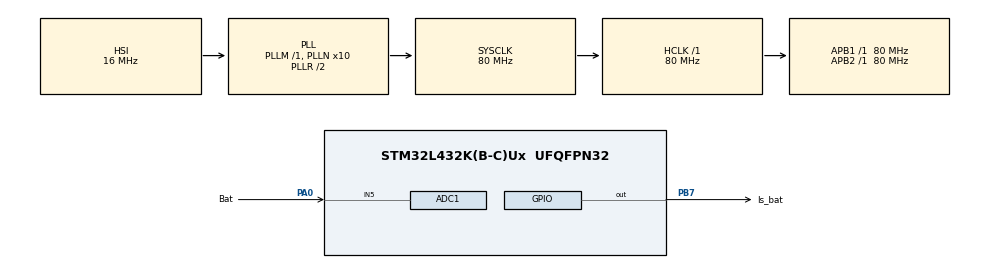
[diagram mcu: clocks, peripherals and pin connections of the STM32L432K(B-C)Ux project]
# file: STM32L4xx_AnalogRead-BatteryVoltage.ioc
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ADC1.Channel-0\#ChannelRegularConversion=ADC_CHANNEL_5
ADC1.ContinuousConvMode=ENABLE
ADC1.NbrOfConversionFlag=1
ADC1.OffsetNumber-0\#ChannelRegularConversion=ADC_OFFSET_NONE
ADC1.Rank-0\#ChannelRegularConversion=1
ADC1.SamplingTime-0\#ChannelRegularConversion=ADC_SAMPLETIME_2CYCLES_5
ADC1.master=1
Mcu.Family=STM32L4
Mcu.Name=STM32L432K(B-C)Ux
Mcu.Package=UFQFPN32
NVIC.ADC1_IRQn=true\:0\:0\:false\:false\:true\:true\:true\:true
NVIC.PriorityGroup=NVIC_PRIORITYGROUP_4
NVIC.RTC_WKUP_IRQn=true\:0\:0\:false\:false\:true\:true\:true\:true
PA0.GPIO_Label=Bat
PA0.Signal=ADCx_IN5
PA13\ (JTMS-SWDIO).Mode=Trace_Asynchronous_SW
PA13\ (JTMS-SWDIO).Signal=SYS_JTMS-SWDIO
PA14\ (JTCK-SWCLK).Mode=Trace_Asynchronous_SW
PA14\ (JTCK-SWCLK).Signal=SYS_JTCK-SWCLK
PB3\ (JTDO-TRACESWO).Mode=Trace_Asynchronous_SW
PB3\ (JTDO-TRACESWO).Signal=SYS_JTDO-SWO
PB7.GPIO_Label=ls_bat
PB7.Signal=GPIO_Output
PC14-OSC32_IN\ (PC14).Mode=LSE-External-Oscillator
PC14-OSC32_IN\ (PC14).Signal=RCC_OSC32_IN
PC15-OSC32_OUT\ (PC15).Mode=LSE-External-Oscillator
PC15-OSC32_OUT\ (PC15).Signal=RCC_OSC32_OUT
ProjectManager.HeapSize=0x200
ProjectManager.StackSize=0x400
ProjectManager.TargetToolchain=STM32CubeIDE
RCC.ADCFreq_Value=64000000
RCC.AHBFreq_Value=80000000
RCC.APB1Freq_Value=80000000
RCC.APB1TimFreq_Value=80000000
RCC.APB2Freq_Value=80000000
RCC.APB2TimFreq_Value=80000000
RCC.CortexFreq_Value=80000000
RCC.HCLKFreq_Value=80000000
RCC.HSE_VALUE=8000000
RCC.HSI48_VALUE=48000000
RCC.HSI_VALUE=16000000
RCC.MSI_VALUE=4000000
RCC.PLLN=10
RCC.PLLSAI1Q=RCC_PLLQ_DIV4
RCC.PLLSourceVirtual=RCC_PLLSOURCE_HSI
RCC.RTCClockSelection=RCC_RTCCLKSOURCE_LSE
RCC.SYSCLKFreq_VALUE=80000000
RCC.SYSCLKSource=RCC_SYSCLKSOURCE_PLLCLK
RCC.USBFreq_Value=32000000
RCC.VCOOutputFreq_Value=160000000
RTC.WakeUpClock=RTC_WAKEUPCLOCK_CK_SPRE_16BITS
SH.ADCx_IN5.0=ADC1_IN5,IN5-Single-Ended
VP_RNG_VS_RNG.Mode=RNG_Activate
VP_RTC_VS_RTC_Activate.Mode=RTC_Enabled
VP_RTC_VS_RTC_Calendar.Mode=RTC_Calendar
VP_RTC_VS_RTC_WakeUp_intern.Mode=WakeUp
board=custom

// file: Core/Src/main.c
/* USER CODE BEGIN Header */
/**
  ******************************************************************************
  * @file           : main.c
  * @brief          : Main program body
  ******************************************************************************
  * @attention
  *
  * Copyright (c) 2023 STMicroelectronics.
  * All rights reserved.
  *
  * This software is licensed under terms that can be found in the LICENSE file
  * in the root directory of this software component.
  * If no LICENSE file comes with this software, it is provided AS-IS.
  *
  ******************************************************************************
  */
/* USER CODE END Header */
#include "main.h"
#include <stdio.h>

ADC_HandleTypeDef hadc1;

RNG_HandleTypeDef hrng;

RTC_HandleTypeDef hrtc;

void SystemClock_Config(void);
void PeriphCommonClock_Config(void);
static void MX_GPIO_Init(void);
static void MX_ADC1_Init(void);
static void MX_RNG_Init(void);
static void MX_RTC_Init(void);

/* USER CODE BEGIN 0 */
int _write(int file, char *ptr, int len){
     int DataIdx;
     for (DataIdx = 0; DataIdx < len; DataIdx++){
         ITM_SendChar((*ptr++));
     }
     return len;
}

void readBat(){
	uint8_t bat = 0;
	HAL_GPIO_WritePin(ls_bat_GPIO_Port, ls_bat_Pin, SET);
	HAL_Delay(100);
	HAL_ADCEx_Calibration_Start(&hadc1, ADC_SINGLE_ENDED);
	HAL_ADC_Start(&hadc1);
	HAL_ADC_PollForConversion(&hadc1, 20);
	float adc_val = 0;
	for (int i = 0; i < 100; i++) {
		adc_val += HAL_ADC_GetValue(&hadc1);
		HAL_Delay(5);
	}
	HAL_GPIO_WritePin(ls_bat_GPIO_Port, ls_bat_Pin, RESET);
	adc_val = adc_val / 100;
	float vadc = (adc_val / 4096) * 3.3;
	bat = ((vadc * (5.23 + 10) / 10) * 100) - 200;
	printf("battery voltage : %.2fV\n", (bat + 200)/100.0);
}
/* USER CODE END 0 */

int main(void)
{

  /* MCU Configuration--------------------------------------------------------*/

  /* Reset of all peripherals, Initializes the Flash interface and the Systick. */
  HAL_Init();

  /* Configure the system clock */
  SystemClock_Config();

/* Configure the peripherals common clocks */
  PeriphCommonClock_Config();

  /* Initialize all configured peripherals */
  MX_GPIO_Init();
  MX_ADC1_Init();
  MX_RNG_Init();
  MX_RTC_Init();

  /* Infinite loop */
  while (1)
  {

    /* USER CODE BEGIN 3 */
	  readBat();
	  HAL_Delay(500);
  }
  /* USER CODE END 3 */
}

void SystemClock_Config(void)
{
  RCC_OscInitTypeDef RCC_OscInitStruct = {0};
  RCC_ClkInitTypeDef RCC_ClkInitStruct = {0};

  /** Configure the main internal regulator output voltage
  */
  if (HAL_PWREx_ControlVoltageScaling(PWR_REGULATOR_VOLTAGE_SCALE1) != HAL_OK)
  {
    Error_Handler();
  }

  /** Configure LSE Drive Capability
  */
  HAL_PWR_EnableBkUpAccess();
  __HAL_RCC_LSEDRIVE_CONFIG(RCC_LSEDRIVE_LOW);

  /** Initializes the RCC Oscillators according to the specified parameters
  * in the RCC_OscInitTypeDef structure.
  */
  RCC_OscInitStruct.OscillatorType = RCC_OSCILLATORTYPE_HSI|RCC_OSCILLATORTYPE_LSE;
  RCC_OscInitStruct.LSEState = RCC_LSE_ON;
  RCC_OscInitStruct.HSIState = RCC_HSI_ON;
  RCC_OscInitStruct.HSICalibrationValue = RCC_HSICALIBRATION_DEFAULT;
  RCC_OscInitStruct.PLL.PLLState = RCC_PLL_ON;
  RCC_OscInitStruct.PLL.PLLSource = RCC_PLLSOURCE_HSI;
  RCC_OscInitStruct.PLL.PLLM = 1;
  RCC_OscInitStruct.PLL.PLLN = 10;
  RCC_OscInitStruct.PLL.PLLP = RCC_PLLP_DIV7;
  RCC_OscInitStruct.PLL.PLLQ = RCC_PLLQ_DIV2;
  RCC_OscInitStruct.PLL.PLLR = RCC_PLLR_DIV2;
  if (HAL_RCC_OscConfig(&RCC_OscInitStruct) != HAL_OK)
  {
    Error_Handler();
  }

  /** Initializes the CPU, AHB and APB buses clocks
  */
  RCC_ClkInitStruct.ClockType = RCC_CLOCKTYPE_HCLK|RCC_CLOCKTYPE_SYSCLK
                              |RCC_CLOCKTYPE_PCLK1|RCC_CLOCKTYPE_PCLK2;
  RCC_ClkInitStruct.SYSCLKSource = RCC_SYSCLKSOURCE_PLLCLK;
  RCC_ClkInitStruct.AHBCLKDivider = RCC_SYSCLK_DIV1;
  RCC_ClkInitStruct.APB1CLKDivider = RCC_HCLK_DIV1;
  RCC_ClkInitStruct.APB2CLKDivider = RCC_HCLK_DIV1;

  if (HAL_RCC_ClockConfig(&RCC_ClkInitStruct, FLASH_LATENCY_4) != HAL_OK)
  {
    Error_Handler();
  }
}

void PeriphCommonClock_Config(void)
{
  RCC_PeriphCLKInitTypeDef PeriphClkInit = {0};

  /** Initializes the peripherals clock
  */
  PeriphClkInit.PeriphClockSelection = RCC_PERIPHCLK_RNG|RCC_PERIPHCLK_ADC;
  PeriphClkInit.AdcClockSelection = RCC_ADCCLKSOURCE_PLLSAI1;
  PeriphClkInit.RngClockSelection = RCC_RNGCLKSOURCE_PLLSAI1;
  PeriphClkInit.PLLSAI1.PLLSAI1Source = RCC_PLLSOURCE_HSI;
  PeriphClkInit.PLLSAI1.PLLSAI1M = 1;
  PeriphClkInit.PLLSAI1.PLLSAI1N = 8;
  PeriphClkInit.PLLSAI1.PLLSAI1P = RCC_PLLP_DIV7;
  PeriphClkInit.PLLSAI1.PLLSAI1Q = RCC_PLLQ_DIV4;
  PeriphClkInit.PLLSAI1.PLLSAI1R = RCC_PLLR_DIV2;
  PeriphClkInit.PLLSAI1.PLLSAI1ClockOut = RCC_PLLSAI1_48M2CLK|RCC_PLLSAI1_ADC1CLK;
  if (HAL_RCCEx_PeriphCLKConfig(&PeriphClkInit) != HAL_OK)
  {
    Error_Handler();
  }
}

static void MX_ADC1_Init(void)
{

  ADC_ChannelConfTypeDef sConfig = {0};

  /** Common config
  */
  hadc1.Instance = ADC1;
  hadc1.Init.ClockPrescaler = ADC_CLOCK_ASYNC_DIV1;
  hadc1.Init.Resolution = ADC_RESOLUTION_12B;
  hadc1.Init.DataAlign = ADC_DATAALIGN_RIGHT;
  hadc1.Init.ScanConvMode = ADC_SCAN_DISABLE;
  hadc1.Init.EOCSelection = ADC_EOC_SINGLE_CONV;
  hadc1.Init.LowPowerAutoWait = DISABLE;
  hadc1.Init.ContinuousConvMode = ENABLE;
  hadc1.Init.NbrOfConversion = 1;
  hadc1.Init.DiscontinuousConvMode = DISABLE;
  hadc1.Init.ExternalTrigConv = ADC_SOFTWARE_START;
  hadc1.Init.ExternalTrigConvEdge = ADC_EXTERNALTRIGCONVEDGE_NONE;
  hadc1.Init.DMAContinuousRequests = DISABLE;
  hadc1.Init.Overrun = ADC_OVR_DATA_PRESERVED;
  hadc1.Init.OversamplingMode = DISABLE;
  if (HAL_ADC_Init(&hadc1) != HAL_OK)
  {
    Error_Handler();
  }

  /** Configure Regular Channel
  */
  sConfig.Channel = ADC_CHANNEL_5;
  sConfig.Rank = ADC_REGULAR_RANK_1;
  sConfig.SamplingTime = ADC_SAMPLETIME_2CYCLES_5;
  sConfig.SingleDiff = ADC_SINGLE_ENDED;
  sConfig.OffsetNumber = ADC_OFFSET_NONE;
  sConfig.Offset = 0;
  if (HAL_ADC_ConfigChannel(&hadc1, &sConfig) != HAL_OK)
  {
    Error_Handler();
  }

}

static void MX_RNG_Init(void)
{

  hrng.Instance = RNG;
  if (HAL_RNG_Init(&hrng) != HAL_OK)
  {
    Error_Handler();
  }

}

static void MX_RTC_Init(void)
{

  RTC_TimeTypeDef sTime = {0};
  RTC_DateTypeDef sDate = {0};

  /** Initialize RTC Only
  */
  hrtc.Instance = RTC;
  hrtc.Init.HourFormat = RTC_HOURFORMAT_24;
  hrtc.Init.AsynchPrediv = 127;
  hrtc.Init.SynchPrediv = 255;
  hrtc.Init.OutPut = RTC_OUTPUT_DISABLE;
  hrtc.Init.OutPutRemap = RTC_OUTPUT_REMAP_NONE;
  hrtc.Init.OutPutPolarity = RTC_OUTPUT_POLARITY_HIGH;
  hrtc.Init.OutPutType = RTC_OUTPUT_TYPE_OPENDRAIN;
  if (HAL_RTC_Init(&hrtc) != HAL_OK)
  {
    Error_Handler();
  }

  /** Initialize RTC and set the Time and Date
  */
  sTime.Hours = 0x0;
  sTime.Minutes = 0x0;
  sTime.Seconds = 0x0;
  sTime.DayLightSaving = RTC_DAYLIGHTSAVING_NONE;
  sTime.StoreOperation = RTC_STOREOPERATION_RESET;
  if (HAL_RTC_SetTime(&hrtc, &sTime, RTC_FORMAT_BCD) != HAL_OK)
  {
    Error_Handler();
  }
  sDate.WeekDay = RTC_WEEKDAY_MONDAY;
  sDate.Month = RTC_MONTH_JANUARY;
  sDate.Date = 0x1;
  sDate.Year = 0x0;

  if (HAL_RTC_SetDate(&hrtc, &sDate, RTC_FORMAT_BCD) != HAL_OK)
  {
    Error_Handler();
  }

}

static void MX_GPIO_Init(void)
{
  GPIO_InitTypeDef GPIO_InitStruct = {0};

  /* GPIO Ports Clock Enable */
  __HAL_RCC_GPIOC_CLK_ENABLE();
  __HAL_RCC_GPIOA_CLK_ENABLE();
  __HAL_RCC_GPIOB_CLK_ENABLE();

  /*Configure GPIO pin Output Level */
  HAL_GPIO_WritePin(ls_bat_GPIO_Port, ls_bat_Pin, GPIO_PIN_RESET);

  /*Configure GPIO pin : ls_bat_Pin */
  GPIO_InitStruct.Pin = ls_bat_Pin;
  GPIO_InitStruct.Mode = GPIO_MODE_OUTPUT_PP;
  GPIO_InitStruct.Pull = GPIO_NOPULL;
  GPIO_InitStruct.Speed = GPIO_SPEED_FREQ_LOW;
  HAL_GPIO_Init(ls_bat_GPIO_Port, &GPIO_InitStruct);

}

void Error_Handler(void)
{
  __disable_irq();
  while (1)
  {
  }
}
